# STM32F303 register map
File version: 1.4
CPU: CM4 r1p0, little endian, no MPU, no FPU, 4 interrupt priority bits
Registers are 32-bit, read-write, reset 0x0 unless marked. A register's access mark holds for its fields unless they carry their own. Offsets are from the block's base; [hi:lo] are bit positions; {n}, {i} and the like mark numbered series; 'fields as' and 'values as' point back to an identical list.

## TIM16 — General-purpose-timers
Base 0x40014400
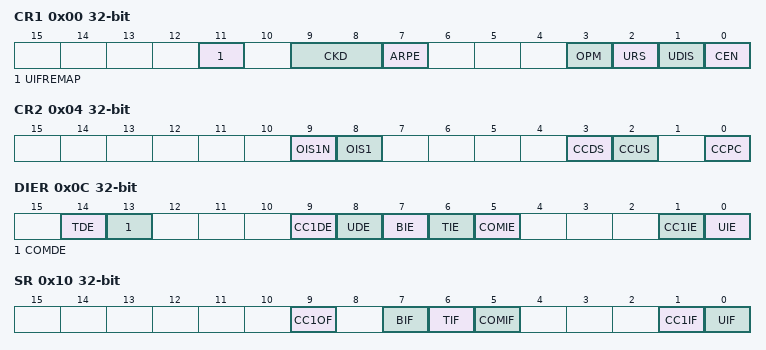
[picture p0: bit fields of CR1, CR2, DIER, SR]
0x00 CR1 — control register 1
  [11] UIFREMAP — UIF status bit remapping
  [9:8] CKD — Clock division
    0=Div1 (t_DTS = t_CK_INT); 1=Div2 (t_DTS = 2 × t_CK_INT); 2=Div4 (t_DTS = 4 × t_CK_INT)
  [7] ARPE — Auto-reload preload enable
    0=Disabled (TIMx_APRR register is not buffered); 1=Enabled (TIMx_APRR register is buffered)
  [3] OPM — One-pulse mode
    0=Not stopped at update event; 1=Stopped (Counter stops counting at next update event)
  [2] URS — Update request source
    0=AnyEvent (Any of counter overflow/underflow, setting UG, or update through slave mode, generates an update interrupt or DMA request); 1=CounterOnly (Only counter overflow/underflow generates an update interrupt or DMA request)
  [1] UDIS — Update disable
    0=Enabled (Update event enabled); 1=Disabled (Update event disabled)
  [0] CEN — Counter enable
    0=Disabled (Counter disabled); 1=Enabled (Counter enabled)
0x04 CR2 — control register 2
  [9] OIS1N — Output Idle state 1
    0=Low (OC1N=0 after a dead-time when MOE=0); 1=High (OC1N=1 after a dead-time when MOE=0)
  [8] OIS1 — Output Idle state 1
    0=Low (OC1=0 (after a dead-time if OC1N is implemented) when MOE=0); 1=High (OC1=1 (after a dead-time if OC1N is implemented) when MOE=0)
  [3] CCDS — Capture/compare DMA selection
    0=OnCompare (CCx DMA request sent when CCx event occurs); 1=OnUpdate (CCx DMA request sent when update event occurs)
  [2] CCUS — Capture/compare control update selection
    0=Default (Capture/compare are updated only by setting the COMG bit); 1=WithRisingEdge (Capture/compare are updated by setting the COMG bit or when an rising edge occurs on TRGI)
  [0] CCPC — Capture/compare preloaded control
    0=NotPreloaded (CCxE, CCxNE and OCxM bits are not preloaded); 1=Preloaded (CCxE, CCxNE and OCxM bits are preloaded)
0x0C DIER — DMA/Interrupt enable register
  [14] TDE — Trigger DMA request enable
  [13] COMDE — COM DMA request enable
  [9] CC1DE — Capture/Compare 1 DMA request enable
    0=Disabled (CC1 DMA request disabled); 1=Enabled (CC1 DMA request enabled)
  [8] UDE — Update DMA request enable
  [7] BIE — Break interrupt enable
    0=Disabled (Break interrupt disabled); 1=Enabled (Break interrupt enabled)
  [6] TIE — Trigger interrupt enable
  [5] COMIE — COM interrupt enable
    0=Disabled (COM interrupt disabled); 1=Enabled (COM interrupt enabled)
  [1] CC1IE — Capture/Compare 1 interrupt enable
    0=Disabled (CC1 interrupt disabled); 1=Enabled (CC1 interrupt enabled)
  [0] UIE — Update interrupt enable
    0=Disabled (Update interrupt disabled); 1=Enabled (Update interrupt enabled)
0x10 SR — status register
  [9] CC1OF — Capture/Compare 1 overcapture flag
  [7] BIF — Break interrupt flag
  [6] TIF — Trigger interrupt flag
  [5] COMIF — COM interrupt flag
  [1] CC1IF — Capture/compare 1 interrupt flag
  [0] UIF — Update interrupt flag
    0=Clear (No update occurred); 1=UpdatePending (Update interrupt pending.)
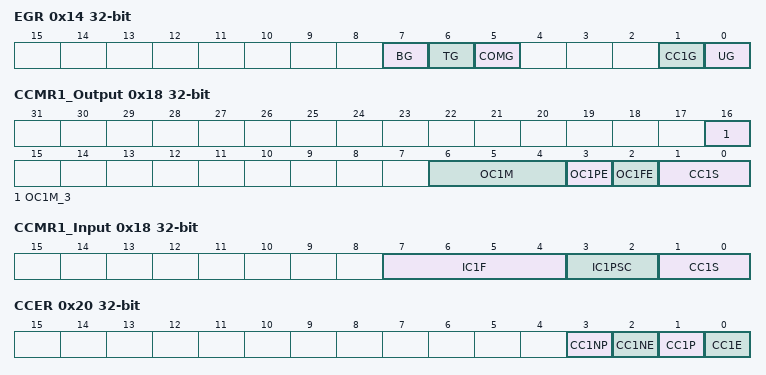
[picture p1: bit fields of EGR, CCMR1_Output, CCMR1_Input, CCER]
0x14 EGR wo — event generation register
  [7] BG — Break generation
  [6] TG — Trigger generation
  [5] COMG — Capture/Compare control update generation
  [1] CC1G — Capture/compare 1 generation
  [0] UG — Update generation
    1=Update (Re-initializes the timer counter and generates an update of the registers.)
0x18 CCMR1_Output — capture/compare mode register (output mode)
  [16] OC1M_3 — Output Compare 1 mode
  [6:4] OC1M — Output Compare 1 mode
    0=Frozen (The comparison between the output compare register TIMx_CCRy and the counter TIMx_CNT has no effect on the outputs); 1=ActiveOnMatch (Set channel to active level on match. OCyREF signal is forced high when the counter matches the capture/compare register); 2=InactiveOnMatch (Set channel to inactive level on match. OCyREF signal is forced low when the counter matches the capture/compare register); 3=Toggle (OCyREF toggles when TIMx_CNT=TIMx_CCRy); 4=ForceInactive (OCyREF is forced low); 5=ForceActive (OCyREF is forced high); 6=PwmMode1 (In upcounting, channel is active as long as TIMx_CNT<TIMx_CCRy else inactive. In downcounting, channel is inactive as long as TIMx_CNT>TIMx_CCRy else active); 7=PwmMode2 (Inversely to PwmMode1)
  [3] OC1PE — Output Compare 1 preload enable
  [2] OC1FE — Output Compare 1 fast enable
  [1:0] CC1S — Capture/Compare 1 selection
0x18 CCMR1_Input (alternate view of CCMR1_Output) — capture/compare mode register 1 (input mode)
  [7:4] IC1F — Input capture 1 filter
  [3:2] IC1PSC — Input capture 1 prescaler
  [1:0] CC1S — Capture/Compare 1 selection
0x20 CCER — capture/compare enable register
  [3] CC1NP — Capture/Compare 1 output Polarity
  [2] CC1NE — Capture/Compare 1 complementary output enable
  [1] CC1P — Capture/Compare 1 output Polarity
  [0] CC1E — Capture/Compare 1 output enable
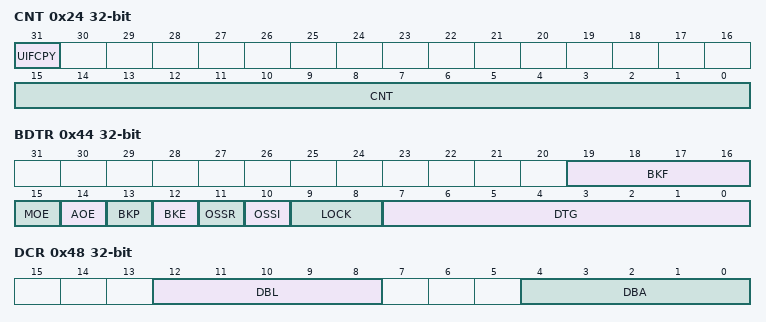
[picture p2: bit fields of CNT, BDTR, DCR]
0x24 CNT access per field — counter
  [31] UIFCPY ro — UIF Copy
  [15:0] CNT rw — counter value
0x28 PSC — prescaler
  [15:0] PSC — Prescaler value
0x2C ARR — auto-reload register
  [15:0] ARR — Auto-reload value
0x30 RCR — repetition counter register
  [7:0] REP — Repetition counter value
0x34 CCR{i} (i=1..1; step 0x0) — capture/compare register
  [15:0] CCR — Capture/Compare value
0x44 BDTR — break and dead-time register
  [19:16] BKF — Break filter
  [15] MOE — Main output enable
  [14] AOE — Automatic output enable
  [13] BKP — Break polarity
  [12] BKE — Break enable
  [11] OSSR — Off-state selection for Run mode
  [10] OSSI — Off-state selection for Idle mode
  [9:8] LOCK — Lock configuration
  [7:0] DTG — Dead-time generator setup
0x48 DCR — DMA control register
  [12:8] DBL — DMA burst length
  [4:0] DBA — DMA base address
0x4C DMAR — DMA address for full transfer
  [15:0] DMAB — DMA register for burst accesses
0x50 OR — option register

## TIM17 — General purpose timer
Base 0x40014800
Registers as TIM16, without OR; these are added or differ:
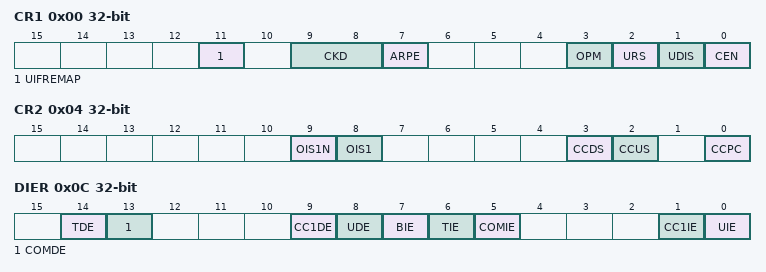
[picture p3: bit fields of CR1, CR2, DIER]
0x00 CR1 — control register 1
  [11] UIFREMAP — UIF status bit remapping
  [9:8] CKD — Clock division
    0=Div1 (t_DTS = t_CK_INT); 1=Div2 (t_DTS = 2 × t_CK_INT); 2=Div4 (t_DTS = 4 × t_CK_INT)
  [7] ARPE — Auto-reload preload enable
    0=Disabled (TIMx_APRR register is not buffered); 1=Enabled (TIMx_APRR register is buffered)
  [3] OPM — One-pulse mode
  [2] URS — Update request source
    values as TIM16.CR1.URS
  [1] UDIS — Update disable
    0=Enabled (Update event enabled); 1=Disabled (Update event disabled)
  [0] CEN — Counter enable
    0=Disabled (Counter disabled); 1=Enabled (Counter enabled)
0x04 CR2 — control register 2
  [9] OIS1N — Output Idle state 1
  [8] OIS1 — Output Idle state 1
  [3] CCDS — Capture/compare DMA selection
  [2] CCUS — Capture/compare control update selection
  [0] CCPC — Capture/compare preloaded control
0x0C DIER — DMA/Interrupt enable register
  [14] TDE — Trigger DMA request enable
  [13] COMDE — COM DMA request enable
  [9] CC1DE — Capture/Compare 1 DMA request enable
  [8] UDE — Update DMA request enable
  [7] BIE — Break interrupt enable
  [6] TIE — Trigger interrupt enable
  [5] COMIE — COM interrupt enable
  [1] CC1IE — Capture/Compare 1 interrupt enable
  [0] UIE — Update interrupt enable
    0=Disabled (Update interrupt disabled); 1=Enabled (Update interrupt enabled)
